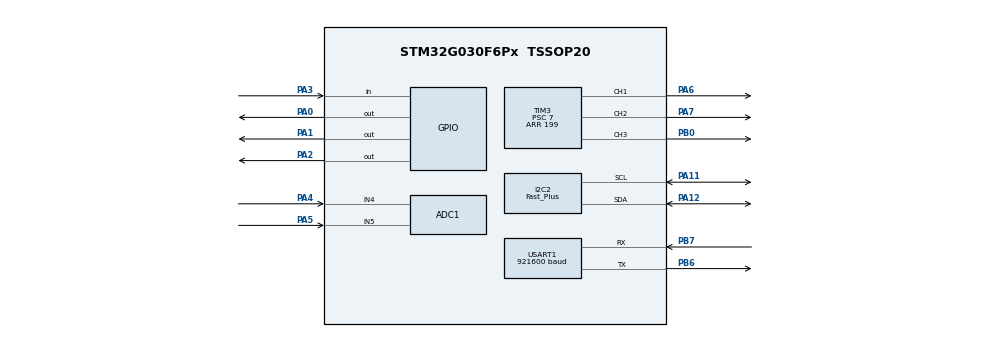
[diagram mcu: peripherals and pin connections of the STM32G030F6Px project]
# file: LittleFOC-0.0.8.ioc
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ADC1.ClockPrescaler=ADC_CLOCK_SYNC_PCLK_DIV2
ADC1.ContinuousConvMode=DISABLE
ADC1.DMAContinuousRequests=ENABLE
ADC1.DataAlign=ADC_DATAALIGN_LEFT
ADC1.DiscontinuousConvMode=DISABLE
ADC1.EOCSelection=ADC_EOC_SEQ_CONV
ADC1.ExternalTrigConv=ADC_EXTERNALTRIG_T1_CC4
ADC1.ExternalTrigConvEdge=ADC_EXTERNALTRIGCONVEDGE_RISING
ADC1.LowPowerAutoPowerOff=DISABLE
ADC1.NbrOfConversion=1
ADC1.NbrOfConversionFlag=0
ADC1.Overrun=ADC_OVR_DATA_OVERWRITTEN
ADC1.SamplingTimeCommon1=ADC_SAMPLETIME_1CYCLE_5
ADC1.ScanConvMode=ADC_SCAN_SEQ_FIXED
ADC1.SelectedChannel=ADC_CHANNEL_4|ADC_CHANNEL_5
ADC1.Sequencer=NOT_FULLY_CONFIGURABLE
ADC1.master=1
Dma.ADC1.0.Direction=DMA_PERIPH_TO_MEMORY
Dma.ADC1.0.EventEnable=DISABLE
Dma.ADC1.0.Instance=DMA1_Channel2
Dma.ADC1.0.MemDataAlignment=DMA_MDATAALIGN_HALFWORD
Dma.ADC1.0.MemInc=DMA_MINC_ENABLE
Dma.ADC1.0.Mode=DMA_CIRCULAR
Dma.ADC1.0.PeriphDataAlignment=DMA_PDATAALIGN_HALFWORD
Dma.ADC1.0.PeriphInc=DMA_PINC_DISABLE
Dma.ADC1.0.Polarity=HAL_DMAMUX_REQ_GEN_RISING
Dma.ADC1.0.Priority=DMA_PRIORITY_LOW
Dma.ADC1.0.RequestNumber=1
Dma.ADC1.0.SignalID=NONE
Dma.ADC1.0.SyncEnable=DISABLE
Dma.ADC1.0.SyncPolarity=HAL_DMAMUX_SYNC_NO_EVENT
Dma.ADC1.0.SyncRequestNumber=1
Dma.ADC1.0.SyncSignalID=NONE
Dma.I2C2_RX.3.Direction=DMA_PERIPH_TO_MEMORY
Dma.I2C2_RX.3.EventEnable=DISABLE
Dma.I2C2_RX.3.Instance=DMA1_Channel1
Dma.I2C2_RX.3.MemDataAlignment=DMA_MDATAALIGN_BYTE
Dma.I2C2_RX.3.MemInc=DMA_MINC_ENABLE
Dma.I2C2_RX.3.Mode=DMA_CIRCULAR
Dma.I2C2_RX.3.PeriphDataAlignment=DMA_PDATAALIGN_BYTE
Dma.I2C2_RX.3.PeriphInc=DMA_PINC_DISABLE
Dma.I2C2_RX.3.Polarity=HAL_DMAMUX_REQ_GEN_RISING
Dma.I2C2_RX.3.Priority=DMA_PRIORITY_LOW
Dma.I2C2_RX.3.RequestNumber=1
Dma.I2C2_RX.3.SignalID=NONE
Dma.I2C2_RX.3.SyncEnable=DISABLE
Dma.I2C2_RX.3.SyncPolarity=HAL_DMAMUX_SYNC_NO_EVENT
Dma.I2C2_RX.3.SyncRequestNumber=1
Dma.I2C2_RX.3.SyncSignalID=NONE
Dma.Request0=ADC1
Dma.Request1=USART1_RX
Dma.Request2=USART1_TX
Dma.Request3=I2C2_RX
Dma.USART1_RX.1.Direction=DMA_PERIPH_TO_MEMORY
Dma.USART1_RX.1.EventEnable=DISABLE
Dma.USART1_RX.1.Instance=DMA1_Channel3
Dma.USART1_RX.1.MemDataAlignment=DMA_MDATAALIGN_BYTE
Dma.USART1_RX.1.MemInc=DMA_MINC_ENABLE
Dma.USART1_RX.1.Mode=DMA_NORMAL
Dma.USART1_RX.1.PeriphDataAlignment=DMA_PDATAALIGN_BYTE
Dma.USART1_RX.1.PeriphInc=DMA_PINC_DISABLE
Dma.USART1_RX.1.Polarity=HAL_DMAMUX_REQ_GEN_RISING
Dma.USART1_RX.1.Priority=DMA_PRIORITY_HIGH
Dma.USART1_RX.1.RequestNumber=1
Dma.USART1_RX.1.SignalID=NONE
Dma.USART1_RX.1.SyncEnable=DISABLE
Dma.USART1_RX.1.SyncPolarity=HAL_DMAMUX_SYNC_NO_EVENT
Dma.USART1_RX.1.SyncRequestNumber=1
Dma.USART1_RX.1.SyncSignalID=NONE
Dma.USART1_TX.2.Direction=DMA_MEMORY_TO_PERIPH
Dma.USART1_TX.2.EventEnable=DISABLE
Dma.USART1_TX.2.Instance=DMA1_Channel4
Dma.USART1_TX.2.MemDataAlignment=DMA_MDATAALIGN_BYTE
Dma.USART1_TX.2.MemInc=DMA_MINC_ENABLE
Dma.USART1_TX.2.Mode=DMA_NORMAL
Dma.USART1_TX.2.PeriphDataAlignment=DMA_PDATAALIGN_BYTE
Dma.USART1_TX.2.PeriphInc=DMA_PINC_DISABLE
Dma.USART1_TX.2.Polarity=HAL_DMAMUX_REQ_GEN_RISING
Dma.USART1_TX.2.Priority=DMA_PRIORITY_LOW
Dma.USART1_TX.2.RequestNumber=1
Dma.USART1_TX.2.SignalID=NONE
Dma.USART1_TX.2.SyncEnable=DISABLE
Dma.USART1_TX.2.SyncPolarity=HAL_DMAMUX_SYNC_NO_EVENT
Dma.USART1_TX.2.SyncRequestNumber=1
Dma.USART1_TX.2.SyncSignalID=NONE
I2C2.I2C_Speed_Mode=I2C_Fast_Plus
I2C2.Speed=400
I2C2.Timing=0x00301183
Mcu.Family=STM32G0
Mcu.Name=STM32G030F6Px
Mcu.Package=TSSOP20
NVIC.ADC1_IRQn=true\:0\:0\:false\:false\:true\:true\:true\:true
NVIC.DMA1_Ch4_5_DMAMUX1_OVR_IRQn=true\:0\:0\:false\:false\:true\:false\:true\:true
NVIC.DMA1_Channel1_IRQn=true\:0\:0\:false\:false\:true\:false\:true\:true
NVIC.DMA1_Channel2_3_IRQn=true\:1\:0\:true\:false\:true\:false\:true\:true
NVIC.I2C2_IRQn=true\:1\:0\:true\:false\:true\:true\:true\:true
NVIC.TIM17_IRQn=true\:0\:0\:false\:false\:true\:true\:true\:true
NVIC.TIM1_BRK_UP_TRG_COM_IRQn=true\:0\:0\:false\:false\:true\:true\:true\:true
NVIC.TIM1_CC_IRQn=true\:0\:0\:false\:false\:true\:true\:true\:true
NVIC.USART1_IRQn=true\:0\:0\:false\:false\:true\:true\:true\:true
PA0.Signal=GPIO_Output
PA1.Signal=GPIO_Output
PA11\ [PA9].Mode=I2C
PA11\ [PA9].Signal=I2C2_SCL
PA12\ [PA10].Mode=I2C
PA12\ [PA10].Signal=I2C2_SDA
PA13.Mode=Serial_Wire
PA13.Signal=SYS_SWDIO
PA14-BOOT0.Mode=Serial_Wire
PA14-BOOT0.Signal=SYS_SWCLK
PA14-BOOT0__PA15.StandardMode=true
PA2.Signal=GPIO_Output
PA3.Signal=GPIO_Input
PA4.Mode=IN4
PA4.Signal=ADC1_IN4
PA5.Mode=IN5
PA5.Signal=ADC1_IN5
PA6.Signal=S_TIM3_CH1
PA7.Signal=S_TIM3_CH2
PB0.Signal=S_TIM3_CH3
PB0__PB1__PB2__PA8.StandardMode=true
PB3__PB4__PB5__PB6.StandardMode=true
PB6.Mode=Asynchronous
PB6.Signal=USART1_TX
PB7.Mode=Asynchronous
PB7.Signal=USART1_RX
PB7__PB8.StandardMode=true
PC14-OSC32_IN\ (PC14).Mode=HSE-External-Clock-Source
PC14-OSC32_IN\ (PC14).Signal=RCC_OSC_IN
PC14-OSC32_IN\ (PC14)__PB9.StandardMode=true
PC15-OSC32_OUT\ (PC15).Mode=OSC enable
PC15-OSC32_OUT\ (PC15).Signal=RCC_OSC_EN
ProjectManager.HeapSize=0x400
ProjectManager.StackSize=0x800
ProjectManager.TargetToolchain=MDK-ARM V5.32
RCC.ADCFreq_Value=64000000
RCC.AHBFreq_Value=64000000
RCC.CortexFreq_Value=64000000
RCC.EXTERNAL_CLOCK_VALUE=12288000
RCC.HCLKFreq_Value=64000000
RCC.HSE_VALUE=16000000
RCC.HSI_VALUE=16000000
RCC.LSE_VALUE=32768
RCC.PLLM=RCC_PLLM_DIV2
RCC.PLLN=16
RCC.PLLSourceVirtual=RCC_PLLSOURCE_HSE
RCC.SYSCLKFreq_VALUE=64000000
RCC.SYSCLKSource=RCC_SYSCLKSOURCE_PLLCLK
RCC.VCOOutputFreq_Value=128000000
SH.S_TIM3_CH1.0=TIM3_CH1,PWM Generation1 CH1
SH.S_TIM3_CH2.0=TIM3_CH2,PWM Generation2 CH2
SH.S_TIM3_CH3.0=TIM3_CH3,PWM Generation3 CH3
TIM1.AutoReloadPreload=TIM_AUTORELOAD_PRELOAD_ENABLE
TIM1.Channel-PWM\ Generation4\ No\ Output=TIM_CHANNEL_4
TIM1.CounterMode=TIM_COUNTERMODE_DOWN
TIM1.Period=198
TIM1.Prescaler=63
TIM1.RepetitionCounter=0
TIM1.TIM_MasterOutputTrigger=TIM_TRGO_RESET
TIM1.TIM_MasterSlaveMode=TIM_MASTERSLAVEMODE_ENABLE
TIM17.Period=1000-1
TIM17.Prescaler=63
TIM3.AutoReloadPreload=TIM_AUTORELOAD_PRELOAD_ENABLE
TIM3.Channel-PWM\ Generation1\ CH1=TIM_CHANNEL_1
TIM3.Channel-PWM\ Generation2\ CH2=TIM_CHANNEL_2
TIM3.Channel-PWM\ Generation3\ CH3=TIM_CHANNEL_3
TIM3.CounterMode=TIM_COUNTERMODE_CENTERALIGNED3
TIM3.OCMode_PWM-PWM\ Generation2\ CH2=TIM_OCMODE_PWM1
TIM3.Period=199
TIM3.Prescaler=7
TIM3.TIM_MasterOutputTrigger=TIM_TRGO_ENABLE
TIM3.TIM_MasterSlaveMode=TIM_MASTERSLAVEMODE_DISABLE
USART1.BaudRate=921600
USART1.VirtualMode-Asynchronous=VM_ASYNC
VP_TIM17_VS_ClockSourceINT.Mode=Enable_Timer
VP_TIM1_VS_ClockSourceINT.Mode=Internal
VP_TIM1_VS_ClockSourceITR.Mode=TriggerSource_ITR3
VP_TIM1_VS_ControllerModeTrigger.Mode=Trigger Mode
VP_TIM1_VS_no_output4.Mode=PWM Generation4 No Output
VP_TIM3_VS_ClockSourceINT.Mode=Internal
board=custom

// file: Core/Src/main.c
/* USER CODE BEGIN Header */
/**
  ******************************************************************************
  * @file           : main.c
  * @brief          : Main program body
  ******************************************************************************
  * @attention
  *
  * <h2><center>&copy; Copyright (c) 2022 STMicroelectronics.
  * All rights reserved.</center></h2>
  *
  * This software component is licensed by ST under BSD 3-Clause license,
  * the "License"; You may not use this file except in compliance with the
  * License. You may obtain a copy of the License at:
  *                        opensource.org/licenses/BSD-3-Clause
  *
  ******************************************************************************
  */
/* USER CODE END Header */
#include "main.h"
#include "adc.h"
#include "dma.h"
#include "i2c.h"
#include "tim.h"
#include "usart.h"
#include "gpio.h"

/* USER CODE BEGIN Includes */
#include "stdio.h"

#include "littleFOC.h"
/* USER CODE END Includes */

/* USER CODE BEGIN PV */
extern uint8_t usart1_tx_buf[usart1_tx_len];
extern uint8_t usart1_rx_buf[usart1_rx_len];
extern uint16_t adc1_buf[2];
extern PMSM_Motor *pmsm_motor;
uint8_t angle = 0;

/* USER CODE END PV */

void SystemClock_Config(void);

int main(void)
{
  /* USER CODE BEGIN 1 */
	uint8_t i;
//	NI_Controller* NIC;
//	q15_t Test_buf[4][3] = {
//	{100,20,1},
//	{-10,20,0},
//	{20,40,1},
//	{4000,20,0}
//	};
  /* USER CODE END 1 */

  /* MCU Configuration--------------------------------------------------------*/

  /* Reset of all peripherals, Initializes the Flash interface and the Systick. */
  LL_APB2_GRP1_EnableClock(LL_APB2_GRP1_PERIPH_SYSCFG);
  LL_APB1_GRP1_EnableClock(LL_APB1_GRP1_PERIPH_PWR);

  /* SysTick_IRQn interrupt configuration */
  NVIC_SetPriority(SysTick_IRQn, 3);

  /* Configure the system clock */
  SystemClock_Config();

  /* Initialize all configured peripherals */
  MX_GPIO_Init();
  MX_DMA_Init();
  MX_TIM17_Init();
  MX_TIM1_Init();
  MX_TIM3_Init();
  MX_USART1_UART_Init();
  MX_I2C2_Init();
  MX_ADC1_Init();
  /* USER CODE BEGIN 2 */

	FOC_Init();
//	NIC = new_NI_Controller();

  /* USER CODE END 2 */

  /* Infinite loop */
  while (1)
  {

    /* USER CODE BEGIN 3 */
		//LL_ADC_REG_StartConversion(ADC1);
		//position_test();
		LL_mDelay(500);
		//printf("%d %d\r\n", pmsm_motor->CurSensor->ADC_BUF[0], pmsm_motor->CurSensor->ADC_BUF[1]);
  }
  /* USER CODE END 3 */
}

void SystemClock_Config(void)
{
  LL_FLASH_SetLatency(LL_FLASH_LATENCY_2);
  while(LL_FLASH_GetLatency() != LL_FLASH_LATENCY_2)
  {
  }

  /* HSE configuration and activation */
  LL_RCC_HSE_EnableBypass();
  LL_RCC_HSE_Enable();
  while(LL_RCC_HSE_IsReady() != 1)
  {
  }

  /* Main PLL configuration and activation */
  LL_RCC_PLL_ConfigDomain_SYS(LL_RCC_PLLSOURCE_HSE, LL_RCC_PLLM_DIV_2, 16, LL_RCC_PLLR_DIV_2);
  LL_RCC_PLL_Enable();
  LL_RCC_PLL_EnableDomain_SYS();
  while(LL_RCC_PLL_IsReady() != 1)
  {
  }

  /* Set AHB prescaler*/
  LL_RCC_SetAHBPrescaler(LL_RCC_SYSCLK_DIV_1);

  /* Sysclk activation on the main PLL */
  LL_RCC_SetSysClkSource(LL_RCC_SYS_CLKSOURCE_PLL);
  while(LL_RCC_GetSysClkSource() != LL_RCC_SYS_CLKSOURCE_STATUS_PLL)
  {
  }

  /* Set APB1 prescaler*/
  LL_RCC_SetAPB1Prescaler(LL_RCC_APB1_DIV_1);

  LL_Init1msTick(64000000);

  /* Update CMSIS variable (which can be updated also through SystemCoreClockUpdate function) */
  LL_SetSystemCoreClock(64000000);
}

void Error_Handler(void)
{
  __disable_irq();
  while (1)
  {
  }
}
